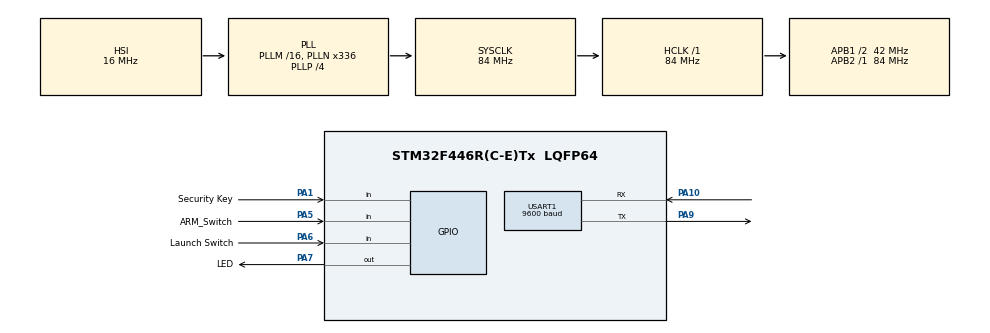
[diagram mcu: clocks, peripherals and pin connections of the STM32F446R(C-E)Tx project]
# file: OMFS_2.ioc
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Dma.Request0=USART1_RX
Dma.USART1_RX.0.Direction=DMA_PERIPH_TO_MEMORY
Dma.USART1_RX.0.FIFOMode=DMA_FIFOMODE_DISABLE
Dma.USART1_RX.0.Instance=DMA2_Stream2
Dma.USART1_RX.0.MemDataAlignment=DMA_MDATAALIGN_BYTE
Dma.USART1_RX.0.MemInc=DMA_MINC_ENABLE
Dma.USART1_RX.0.Mode=DMA_CIRCULAR
Dma.USART1_RX.0.PeriphDataAlignment=DMA_PDATAALIGN_BYTE
Dma.USART1_RX.0.PeriphInc=DMA_PINC_DISABLE
Dma.USART1_RX.0.Priority=DMA_PRIORITY_LOW
Mcu.Family=STM32F4
Mcu.Name=STM32F446R(C-E)Tx
Mcu.Package=LQFP64
NVIC.DMA2_Stream2_IRQn=true\:0\:0\:false\:false\:true\:false\:true\:true
NVIC.PriorityGroup=NVIC_PRIORITYGROUP_0
NVIC.USART1_IRQn=true\:0\:0\:false\:false\:true\:true\:true\:true
PA1.GPIO_Label=Security Key
PA1.Signal=GPIO_Input
PA10.Mode=Asynchronous
PA10.Signal=USART1_RX
PA13.Mode=Serial_Wire
PA13.Signal=SYS_JTMS-SWDIO
PA14.Mode=Serial_Wire
PA14.Signal=SYS_JTCK-SWCLK
PA5.GPIO_Label=ARM_Switch
PA5.Signal=GPIO_Input
PA6.GPIO_Label=Launch Switch
PA6.Signal=GPIO_Input
PA7.GPIO_Label=LED
PA7.Signal=GPIO_Output
PA9.Mode=Asynchronous
PA9.Signal=USART1_TX
PC14-OSC32_IN.Mode=LSE-External-Oscillator
PC14-OSC32_IN.Signal=RCC_OSC32_IN
PC15-OSC32_OUT.Mode=LSE-External-Oscillator
PC15-OSC32_OUT.Signal=RCC_OSC32_OUT
PH0-OSC_IN.Mode=HSE-External-Oscillator
PH0-OSC_IN.Signal=RCC_OSC_IN
PH1-OSC_OUT.Mode=HSE-External-Oscillator
PH1-OSC_OUT.Signal=RCC_OSC_OUT
ProjectManager.HeapSize=0x200
ProjectManager.StackSize=0x400
ProjectManager.TargetToolchain=STM32CubeIDE
RCC.48MHZClocksFreq_Value=84000000
RCC.AHBFreq_Value=84000000
RCC.APB1CLKDivider=RCC_HCLK_DIV2
RCC.APB1Freq_Value=42000000
RCC.APB1TimFreq_Value=84000000
RCC.APB2Freq_Value=84000000
RCC.APB2TimFreq_Value=84000000
RCC.CortexFreq_Value=84000000
RCC.FLatency-AdvancedSettings=FLASH_LATENCY_2
RCC.HCLKFreq_Value=84000000
RCC.HSE_VALUE=8000000
RCC.HSI_VALUE=16000000
RCC.PLLN=336
RCC.PLLP=RCC_PLLP_DIV4
RCC.SYSCLKFreq_VALUE=84000000
RCC.SYSCLKSource=RCC_SYSCLKSOURCE_PLLCLK
RCC.USBFreq_Value=168000000
RCC.VCOOutputFreq_Value=336000000
USART1.BaudRate=9600
USART1.VirtualMode=VM_ASYNC
board=NUCLEO-F446RE

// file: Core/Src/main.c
/* USER CODE BEGIN Header */
/**
  ******************************************************************************
  * @file           : main.c
  * @brief          : Main program body
  ******************************************************************************
  * @attention
  *
  * Copyright (c) 2023 STMicroelectronics.
  * All rights reserved.
  *
  * This software is licensed under terms that can be found in the LICENSE file
  * in the root directory of this software component.
  * If no LICENSE file comes with this software, it is provided AS-IS.
  *
  ******************************************************************************
  */
/* USER CODE END Header */
#include "main.h"

/* USER CODE BEGIN Includes */
#include<stdbool.h>
#include<stdlib.h>
/* USER CODE END Includes */

UART_HandleTypeDef huart1;
DMA_HandleTypeDef hdma_usart1_rx;

void SystemClock_Config(void);
static void MX_GPIO_Init(void);
static void MX_DMA_Init(void);
static void MX_USART1_UART_Init(void);

/* USER CODE BEGIN 0 */
char rx_data[1]={0};
bool Sec_key = 0, Arm_switch = 0, Ign_switch = 0;
bool seq_flag = 0;
//GMFS status Signals
char key_ack='K';
char arm_ack='A';
char launch_ack='L';
char isu_check_ack='C';
char kill='K';
char error_ack='E';
char ignite_ack='I';
void ignition()
{
HAL_GPIO_WritePin(GPIOB, GPIO_PIN_5, 0);
HAL_Delay(100);
}
void isu_pre_check()
{
	;
}
/* USER CODE END 0 */

int main(void)
{

  /* MCU Configuration--------------------------------------------------------*/

  /* Reset of all peripherals, Initializes the Flash interface and the Systick. */
  HAL_Init();

  /* Configure the system clock */
  SystemClock_Config();

  /* Initialize all configured peripherals */
  MX_GPIO_Init();
  MX_DMA_Init();
  MX_USART1_UART_Init();
  /* USER CODE BEGIN 2 */
  HAL_UART_Receive_DMA(&huart1, rx_data, sizeof(rx_data));
  /* USER CODE END 2 */

  /* Infinite loop */
  while (1)
  {

    /* USER CODE BEGIN 3 */
	  if(rx_data=='F')
	  {
	  		HAL_UART_Transmit(&huart1, key_ack, sizeof(key_ack), 100);
	  		if(rx_data=='B')
	  		HAL_UART_Transmit(&huart1, arm_ack, sizeof(arm_ack), 100);
	  		if(rx_data=='D')
	  		isu_pre_check();
	  	    HAL_UART_Transmit(&huart1, isu_check_ack, sizeof(isu_check_ack), 100);
	  	    if(rx_data=='I')
	  	    HAL_UART_Transmit(&huart1, ignite_ack, sizeof(ignite_ack), 100);
	  	    if(rx_data=='L')
	  	    HAL_UART_Transmit(&huart1, launch_ack, sizeof(launch_ack), 100);
	  }
	  else
	  HAL_UART_Transmit(&huart1, error_ack, sizeof(error_ack), 100);
  }
  /* USER CODE END 3 */
}

void SystemClock_Config(void)
{
  RCC_OscInitTypeDef RCC_OscInitStruct = {0};
  RCC_ClkInitTypeDef RCC_ClkInitStruct = {0};

  /** Configure the main internal regulator output voltage
  */
  __HAL_RCC_PWR_CLK_ENABLE();
  __HAL_PWR_VOLTAGESCALING_CONFIG(PWR_REGULATOR_VOLTAGE_SCALE3);

  /** Initializes the RCC Oscillators according to the specified parameters
  * in the RCC_OscInitTypeDef structure.
  */
  RCC_OscInitStruct.OscillatorType = RCC_OSCILLATORTYPE_HSI;
  RCC_OscInitStruct.HSIState = RCC_HSI_ON;
  RCC_OscInitStruct.HSICalibrationValue = RCC_HSICALIBRATION_DEFAULT;
  RCC_OscInitStruct.PLL.PLLState = RCC_PLL_ON;
  RCC_OscInitStruct.PLL.PLLSource = RCC_PLLSOURCE_HSI;
  RCC_OscInitStruct.PLL.PLLM = 16;
  RCC_OscInitStruct.PLL.PLLN = 336;
  RCC_OscInitStruct.PLL.PLLP = RCC_PLLP_DIV4;
  RCC_OscInitStruct.PLL.PLLQ = 2;
  RCC_OscInitStruct.PLL.PLLR = 2;
  if (HAL_RCC_OscConfig(&RCC_OscInitStruct) != HAL_OK)
  {
    Error_Handler();
  }

  /** Initializes the CPU, AHB and APB buses clocks
  */
  RCC_ClkInitStruct.ClockType = RCC_CLOCKTYPE_HCLK|RCC_CLOCKTYPE_SYSCLK
                              |RCC_CLOCKTYPE_PCLK1|RCC_CLOCKTYPE_PCLK2;
  RCC_ClkInitStruct.SYSCLKSource = RCC_SYSCLKSOURCE_PLLCLK;
  RCC_ClkInitStruct.AHBCLKDivider = RCC_SYSCLK_DIV1;
  RCC_ClkInitStruct.APB1CLKDivider = RCC_HCLK_DIV2;
  RCC_ClkInitStruct.APB2CLKDivider = RCC_HCLK_DIV1;

  if (HAL_RCC_ClockConfig(&RCC_ClkInitStruct, FLASH_LATENCY_2) != HAL_OK)
  {
    Error_Handler();
  }
}

static void MX_USART1_UART_Init(void)
{

  huart1.Instance = USART1;
  huart1.Init.BaudRate = 9600;
  huart1.Init.WordLength = UART_WORDLENGTH_8B;
  huart1.Init.StopBits = UART_STOPBITS_1;
  huart1.Init.Parity = UART_PARITY_NONE;
  huart1.Init.Mode = UART_MODE_TX_RX;
  huart1.Init.HwFlowCtl = UART_HWCONTROL_NONE;
  huart1.Init.OverSampling = UART_OVERSAMPLING_16;
  if (HAL_UART_Init(&huart1) != HAL_OK)
  {
    Error_Handler();
  }

}

static void MX_DMA_Init(void)
{

  /* DMA controller clock enable */
  __HAL_RCC_DMA2_CLK_ENABLE();

  /* DMA interrupt init */
  /* DMA2_Stream2_IRQn interrupt configuration */
  HAL_NVIC_SetPriority(DMA2_Stream2_IRQn, 0, 0);
  HAL_NVIC_EnableIRQ(DMA2_Stream2_IRQn);

}

static void MX_GPIO_Init(void)
{
  GPIO_InitTypeDef GPIO_InitStruct = {0};

  /* GPIO Ports Clock Enable */
  __HAL_RCC_GPIOC_CLK_ENABLE();
  __HAL_RCC_GPIOH_CLK_ENABLE();
  __HAL_RCC_GPIOA_CLK_ENABLE();
  __HAL_RCC_GPIOB_CLK_ENABLE();

  /*Configure GPIO pin Output Level */
  HAL_GPIO_WritePin(GPIOB, GPIO_PIN_5, GPIO_PIN_RESET);

  /*Configure GPIO pin : PB5 */
  GPIO_InitStruct.Pin = GPIO_PIN_5;
  GPIO_InitStruct.Mode = GPIO_MODE_OUTPUT_PP;
  GPIO_InitStruct.Pull = GPIO_NOPULL;
  GPIO_InitStruct.Speed = GPIO_SPEED_FREQ_LOW;
  HAL_GPIO_Init(GPIOB, &GPIO_InitStruct);

}

void Error_Handler(void)
{
  __disable_irq();
  while (1)
  {
  }
}
